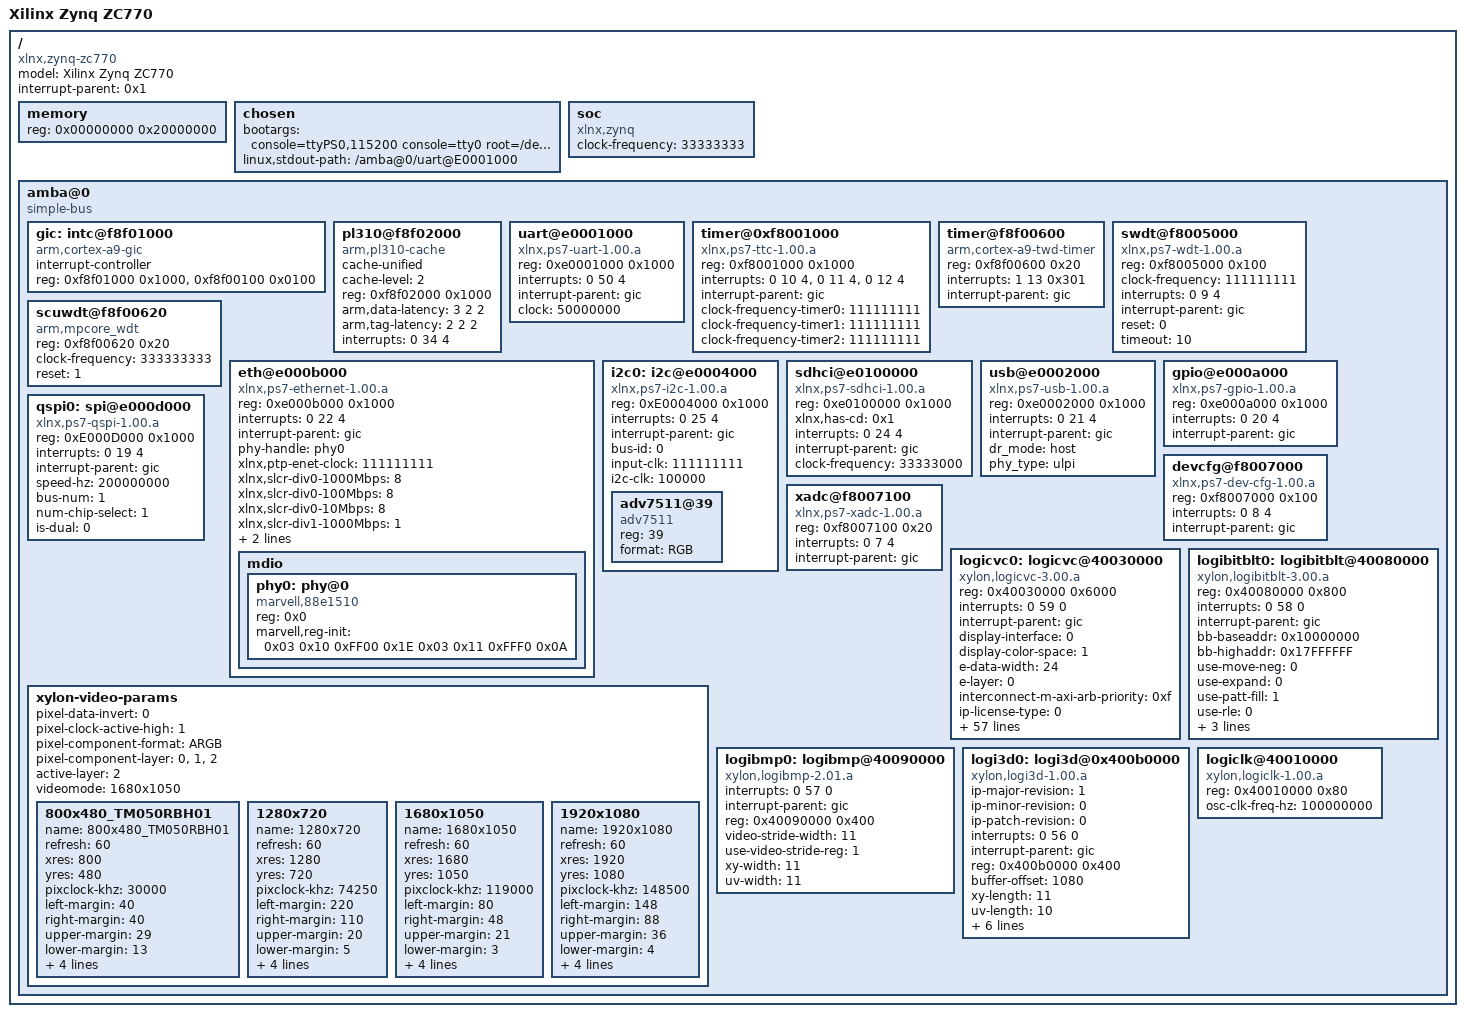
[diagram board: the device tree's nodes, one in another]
/dts-v1/;

/ {
	model = "Xilinx Zynq ZC770";
	compatible = "xlnx,zynq-zc770";
	#address-cells = <0x1>;
	#size-cells = <0x1>;
	interrupt-parent = <0x1>;

	memory {
		device_type = "memory";
		reg = <0x00000000 0x20000000>;
	};
	chosen {
		bootargs = "console=ttyPS0,115200 console=tty0 root=/dev/ram rw initrd=0x00800000,256K noinitrd ip=:::::eth0:dhcp earlyprintk mem=256M memmap=256M$0x10000000 vmalloc=256M";
		linux,stdout-path = "/amba@0/uart@E0001000";
	};

	soc {
		compatible = "xlnx,zynq";
		clock-frequency = <33333333>;
	};

	amba@0 {
		compatible = "simple-bus";
		#address-cells = <0x1>;
		#size-cells = <0x1>;
		ranges;

		gic: intc@f8f01000 {
			interrupt-controller;
			compatible = "arm,cortex-a9-gic";
			#interrupt-cells = <3>;
			reg = <0xf8f01000 0x1000>,
			      <0xf8f00100 0x0100>;
		};

		pl310@f8f02000 {
			compatible = "arm,pl310-cache";
			cache-unified;
			cache-level = <2>;
			reg = <0xf8f02000 0x1000>;
			arm,data-latency = <3 2 2>;
			arm,tag-latency = <2 2 2>;
			interrupts = <0 34 4>;
		};

		uart@e0001000 {
			compatible = "xlnx,ps7-uart-1.00.a";
			reg = <0xe0001000 0x1000>;
			interrupts = <0 50 4>;
			interrupt-parent = <&gic>;
			clock = <50000000>;
		};

		timer@0xf8001000 {
			compatible = "xlnx,ps7-ttc-1.00.a";
			reg = <0xf8001000 0x1000>;
			interrupts = <0 10 4>,<0 11 4>,<0 12 4>;
			interrupt-parent = <&gic>;
			clock-frequency-timer0 = <111111111>;
			clock-frequency-timer1 = <111111111>;
			clock-frequency-timer2 = <111111111>;
		};

		timer@f8f00600 {
			compatible = "arm,cortex-a9-twd-timer";
			reg = <0xf8f00600 0x20>;
			interrupts = <1 13 0x301>;
			interrupt-parent = <&gic>;
		};

		swdt@f8005000 {
			device_type = "watchdog";
			compatible = "xlnx,ps7-wdt-1.00.a";
			reg = <0xf8005000 0x100>;
			clock-frequency = <111111111>;
			interrupts = <0 9 4>;
			interrupt-parent = <&gic>;
			reset = <0>;
			timeout = <10>;
		};

		scuwdt@f8f00620 {
			device_type = "watchdog";
			compatible = "arm,mpcore_wdt";
			reg = <0xf8f00620 0x20>;
			clock-frequency = <333333333>;
			reset = <1>;
		};

		eth@e000b000 {
			compatible = "xlnx,ps7-ethernet-1.00.a";
			reg = <0xe000b000 0x1000>;
			interrupts = <0 22 4>;
			interrupt-parent = <&gic>;
			phy-handle = <&phy0>;
			xlnx,ptp-enet-clock = <111111111>;
			xlnx,slcr-div0-1000Mbps = <8>;
			xlnx,slcr-div0-100Mbps = <8>;
			xlnx,slcr-div0-10Mbps = <8>;
			xlnx,slcr-div1-1000Mbps = <1>;
			xlnx,slcr-div1-100Mbps = <5>;
			xlnx,slcr-div1-10Mbps = <50>;
			#address-cells = <0x1>;
			#size-cells = <0x0>;

                        mdio {
				#address-cells = <1>;
				#size-cells = <0>;
                                phy0: phy@0 {
                                        compatible = "marvell,88e1510";
                                        device_type = "ethernet-phy";
                                        reg = <0x0>;
                                        marvell,reg-init = <0x03 0x10 0xFF00 0x1E 0x03 0x11 0xFFF0 0x0A>;
                                        linux,phandle = <0x2>;
                                };
                        };
		};

		i2c0: i2c@e0004000 {
			compatible = "xlnx,ps7-i2c-1.00.a";
			reg = <0xE0004000 0x1000>;
			interrupts = <0 25 4>;
			interrupt-parent = <&gic>;
			bus-id = <0>;
			input-clk = <111111111>;
			i2c-clk = <100000>;

			#address-cells = <1>;
			#size-cells = <0>;
                        adv7511@39 {
                                #address-cells = <1>;
                                #size-cells = <0>;
                                reg = <39>;
                                compatible = "adv7511";
                                format = "RGB";
                        };
		};

		sdhci@e0100000 {
			compatible = "xlnx,ps7-sdhci-1.00.a";
			reg = <0xe0100000 0x1000>;
			xlnx,has-cd = <0x1>;
			interrupts = <0 24 4>;
			interrupt-parent = <&gic>;
			clock-frequency = <33333000>;
		};

		usb@e0002000 {
			compatible = "xlnx,ps7-usb-1.00.a";
			reg = <0xe0002000 0x1000>;
			interrupts = <0 21 4>;
			interrupt-parent = <&gic>;
			dr_mode = "host";
			phy_type = "ulpi";
		};

		gpio@e000a000 {
			compatible = "xlnx,ps7-gpio-1.00.a";
			reg = <0xe000a000 0x1000>;
			interrupts = <0 20 4>;
			interrupt-parent = <&gic>;
		};

		qspi0: spi@e000d000 {
			compatible = "xlnx,ps7-qspi-1.00.a";
			reg = <0xE000D000 0x1000>;
			interrupts = <0 19 4>;
			interrupt-parent = <&gic>;
			speed-hz = <200000000>;
			bus-num = <1>;
			num-chip-select = <1>;
			#address-cells = <1>;
			#size-cells = <0>;
			is-dual = <0>;
		};

		devcfg@f8007000 {
			compatible = "xlnx,ps7-dev-cfg-1.00.a";
			reg = <0xf8007000 0x100>;
			interrupts = <0 8 4>;
			interrupt-parent = <&gic>;
		};

		xadc@f8007100 {
			compatible = "xlnx,ps7-xadc-1.00.a";
			reg = <0xf8007100 0x20>;
			interrupts = <0 7 4>;
			interrupt-parent = <&gic>;
		};

		logicvc0: logicvc@40030000 {
			compatible = "xylon,logicvc-3.00.a";
			reg = <0x40030000 0x6000>;
			interrupts = <0 59 0>;
			interrupt-parent = <&gic>;
			display-interface = <0>;
			display-color-space = <1>;
			e-data-width = <24>;
			e-layer = <0>;
			interconnect-m-axi-arb-priority = <0xf>;
			ip-license-type = <0>;
			ip-major-revision = <3>;
			ip-minor-revision = <0>;
			ip-patch-level = <0>;
			layer-0-type = <0>;
			layer-0-alpha-mode = <1>;
			layer-0-data-width = <24>;
			layer-0-offset = <7290>;
			layer-1-type = <0>;
			layer-1-alpha-mode = <0>;
			layer-1-data-width = <24>;
			layer-1-offset = <4050>;
			layer-2-type = <0>;
			layer-2-alpha-mode = <0>;
			layer-2-data-width = <24>;
			layer-2-offset = <0>;
			layer-3-type = <0>;
			layer-3-alpha-mode = <3>;
			layer-3-data-width = <8>;
			layer-3-offset = <12960>;
			layer-4-type = <0>;
			layer-4-alpha-mode = <0>;
			layer-4-data-width = <24>;
			layer-4-offset = <11340>;
			buffer-0-offset = <1080>;
			buffer-1-offset = <1080>;
			buffer-2-offset = <1080>;
			buffer-3-offset = <1080>;
			buffer-4-offset = <1080>;
			little-endian = <1>;
			lvds-data-width = <4>;
			mem-burst = <4>;
			mplb-awidth = <32>;
			mplb-dwidth = <64>;
			mplb-native-dwidth = <32>;
			mplb-num-masters = <8>;
			mplb-p2p = <0>;
			mplb-priority = <3>;
			mplb-smallest-slave = <32>;
			mplb-support-bursts = <1>;
			num-of-layers = <5>;
			pixel-data-width = <24>;
			readable-regs = <0>;
			regs-interface = <2>;
			regs-little-endian = <1>;
			row-stride = <2048>;
			use-background = <1>;
			use-e-rgb-input = <0>;
			use-e-vclk-bufgmux = <1>;
			use-io-hw-serializer = <0>;
			use-multiplier = <2>;
			use-serialized-blender = <0>;
			use-size-position = <1>;
			use-xtreme-dsp = <2>;
			vmem-baseaddr = <0x10000000>;
			vmem-highaddr = <0x1FFFFFFF>;
			vmem-data-bus-width = <64>;
			vmem-interface = <2>;
		};

		xylon-video-params {
			pixel-data-invert = <0>;
			pixel-clock-active-high = <1>;
			pixel-component-format = "ARGB";
			pixel-component-layer = <0>,<1>,<2>;
			active-layer = <2>;
			videomode = "1680x1050";
			800x480_TM050RBH01 {
				name = "800x480_TM050RBH01";
				refresh = <60>;
				xres = <800>;
				yres = <480>;
				pixclock-khz = <30000>;
				left-margin = <40>;
				right-margin = <40>;
				upper-margin = <29>;
				lower-margin = <13>;
				hsync-len = <48>;
				vsync-len = <3>;
				sync = <0>;
				vmode = <0>;
			};
			1280x720 {
				name = "1280x720";
				refresh = <60>;
				xres = <1280>;
				yres = <720>;
				pixclock-khz = <74250>;
				left-margin = <220>;
				right-margin = <110>;
				upper-margin = <20>;
				lower-margin = <5>;
				hsync-len = <40>;
				vsync-len = <5>;
				sync = <0>;
				vmode = <0>;
			};
			1680x1050 {
				name = "1680x1050";
				refresh = <60>;
				xres = <1680>;
				yres = <1050>;
				pixclock-khz = <119000>;
				left-margin = <80>;
				right-margin = <48>;
				upper-margin = <21>;
				lower-margin = <3>;
				hsync-len = <32>;
				vsync-len = <6>;
				sync = <0>;
				vmode = <0>;
			};
			1920x1080 {
				name = "1920x1080";
				refresh = <60>;
				xres = <1920>;
				yres = <1080>;
				pixclock-khz = <148500>;
				left-margin = <148>;
				right-margin = <88>;
				upper-margin = <36>;
				lower-margin = <4>;
				hsync-len = <44>;
				vsync-len = <5>;
				sync = <0>;
				vmode = <0>;
			};
		};

		logibitblt0: logibitblt@40080000 {
			compatible = "xylon,logibitblt-3.00.a";
			reg = <0x40080000 0x800>;
			interrupts = <0 58 0>;
			interrupt-parent = <&gic>;
			bb-baseaddr = <0x10000000>;
			bb-highaddr = <0x17FFFFFF>;
			use-move-neg = <0>;
			use-expand = <0>;
			use-patt-fill = <1>;
			use-rle = <0>;
			use-porter-duff = <1>;
			use-aa-font-expand = <1>;
			use-global-alpha = <1>;
		};

		logibmp0: logibmp@40090000 {
			compatible = "xylon,logibmp-2.01.a";
			interrupts = <0 57 0>;
			interrupt-parent = <&gic>;
			reg = <0x40090000 0x400>;
			video-stride-width = <11>;
			use-video-stride-reg = <1>;
			xy-width = <11>;
			uv-width = <11>;
		};

		logi3d0: logi3d@0x400b0000 {
			compatible = "xylon,logi3d-1.00.a";
			ip-major-revision = <1>;
			ip-minor-revision = <0>;
			ip-patch-revision = <0>;
			interrupts = <0 56 0>;
			interrupt-parent = <&gic>;
			reg = <0x400b0000 0x400>;
			buffer-offset = <1080>;
			xy-length = <11>;
			uv-length = <10>;
			use-multitexture = <0>;
			pixel-component-format = "ARGB";
			sw-mem-3d-internal = <0x36000000 0x0a000000>;
			sw-video-mem = <0x30000000 0x1950000>;
			default-fb-name = "/dev/fb2";
			default-cvc-layer = <0 1>;
		};

		logiclk@40010000 {
			compatible = "xylon,logiclk-1.00.a";
			reg = <0x40010000 0x80>;
			osc-clk-freq-hz = <100000000>;
		};
	};
};
